# PIC32MZ1024EFM064 device description
Architecture: MIPS; Family: PIC32MZEF; Series: PIC32MZ
Registers are 32-bit, read-write, no defined reset value unless marked. A register's access mark holds for its fields unless they carry their own. Offsets are from the block's base; [hi:lo] are bit positions; {n}, {i} and the like mark numbered series; 'fields as' and 'values as' point back to an identical list.

## CFG
Instances: CFG 0x1f800000 in periph_pb1_std
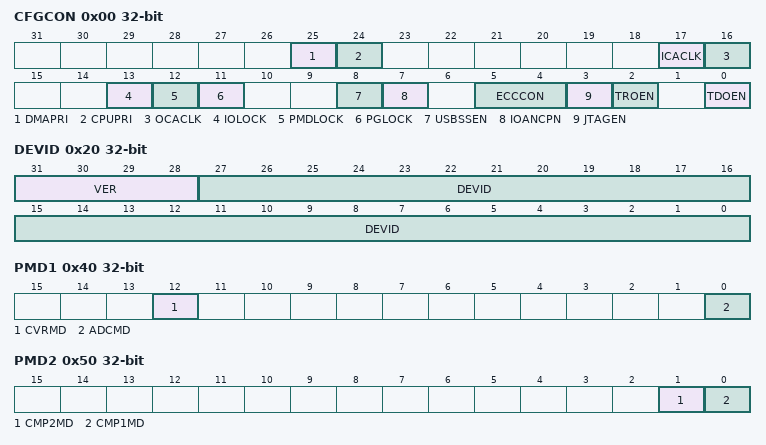
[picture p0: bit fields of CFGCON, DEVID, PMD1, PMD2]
0x00 CFGCON — Configuration Control Register
  [25] DMAPRI — DMA Read and DMA Write Arbitration Priority to SRAM bit(1)
    1=DMA gets High Priority access to SRAM; 0=DMA uses Least Recently Serviced Arbitration (same as other initiators)
  [24] CPUPRI — CPU Arbitration Priority to SRAM When Servicing an Interrupt bit(1)
    1=CPU gets High Priority access to SRAM; 0=CPU uses Least Recently Serviced Arbitration (same as other initiators)
  [17] ICACLK — Input Capture Alternate Clock Selection bit(1)
    1=Input Capture modules use an alternative Timer pair as their timebase clock; 0=All Input Capture modules use Timer2/3 as their timebase clock
  [16] OCACLK — Output Compare Alternate Clock Selection bit(1)
    1=Output Compare modules use an alternative Timer pair as their timebase clock; 0=All Output Compare modules use Timer2/3 as their timebase clock
  [13] IOLOCK — Peripheral Pin Select Lock bit(1)
    1=Peripheral Pin Select is locked. Writes to PPS registers are not allowed; 0=Peripheral Pin Select is not locked. Writes to PPS registers are allowed
  [12] PMDLOCK — Peripheral Module Disable bit(1)
    1=Peripheral module is locked. Writes to PMD registers are not allowed; 0=Peripheral module is not locked. Writes to PMD registers are allowed
  [11] PGLOCK — Permission Group Lock bit(1)
    1=Permission Group registers are locked. Writes to PG registers are not allowed; 0=Permission Group registers are not locked. Writes to PG registers are allowed
  [8] USBSSEN — USB Suspend Sleep Enable bit(1)
    1=USB PHY clock is shut down when Sleep mode is active; 0=USB PHY clock continues to run when Sleep is active
  [7] IOANCPN
  [5:4] ECCCON — Flash ECC Configuration bits
    3=ECC and dynamic ECC are disabled (ECCCON bits are writable); 2=ECC and dynamic ECC are disabled (ECCCON bits are locked); 1=Dynamic Flash ECC is enabled (ECCCON bits are locked); 0=Flash ECC is enabled (ECCCON bits are locked; disables word Flash writes)
  [3] JTAGEN — JTAG Port Enable bit
    1=Enable the JTAG port; 0=Disable the JTAG port
  [2] TROEN — Trace Output Enable bit
    1=Enable trace outputs and start trace clock (trace probe must be present); 0=Disable trace outputs and stop trace clock
  [0] TDOEN — TDO Enable for 2-Wire JTAG
    1=2-wire JTAG protocol uses TDO; 0=2-wire JTAG protocol does not use TDO
0x20 DEVID — Device and Revision ID Register
  [31:28] VER, [27:0] DEVID
0x30 SYSKEY
0x40 PMD1
  [12] CVRMD, [0] ADCMD
0x50 PMD2
  [1] CMP2MD, [0] CMP1MD
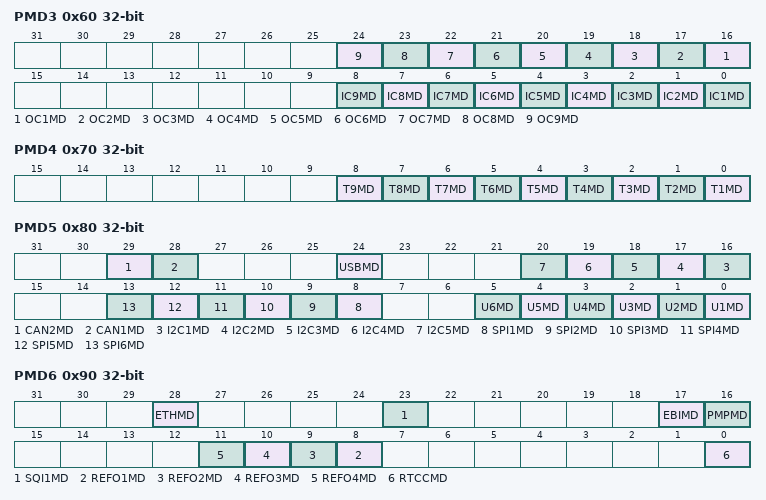
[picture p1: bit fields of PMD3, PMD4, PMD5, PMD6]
0x60 PMD3
  [n+15] OC{n}MD (n=1..9), [n-1] IC{n}MD (n=1..9)
0x70 PMD4
  [n-1] T{n}MD (n=1..9)
0x80 PMD5
  [29] CAN2MD, [28] CAN1MD, [24] USBMD, [n+15] I2C{n}MD (n=1..5), [n+7] SPI{n}MD (n=1..6), [n-1] U{n}MD (n=1..6)
0x90 PMD6
  [28] ETHMD, [23] SQI1MD, [17] EBIMD, [16] PMPMD, [n+7] REFO{n}MD (n=1..4), [0] RTCCMD
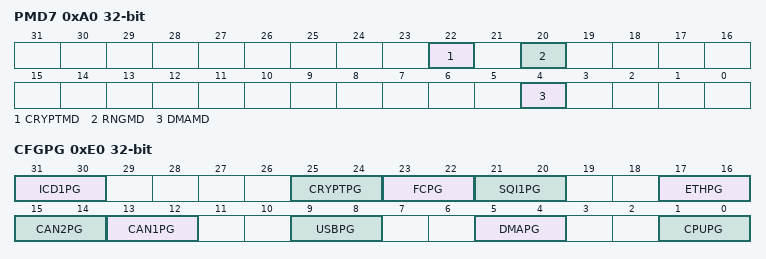
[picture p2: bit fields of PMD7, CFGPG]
0xA0 PMD7
  [22] CRYPTMD, [20] RNGMD, [4] DMAMD
0xE0 CFGPG — Permission Group Configuration Register
  [31:30] ICD1PG
  [25:24] CRYPTPG — Crypto Engine Permission Group bits
    {v}=Initiator is assigned to Permission Group {v} (v=0..3)
  [23:22] FCPG
  [21:20] SQI1PG
  [17:16] ETHPG
  [15:14] CAN2PG
  [13:12] CAN1PG
  [9:8] USBPG
  [5:4] DMAPG
  [1:0] CPUPG
Value list DEVID__VER: 0x10000000=Revision A1; 0x30000000=Revision A3; 0x60000000=Revision B2
Value list CFGCON__IOANCPEN: 128=Charge pump is enabled; 0=Charge pump is disabled

## CMP
Instances: CMP 0x1f84c000 in periph_pb3_std
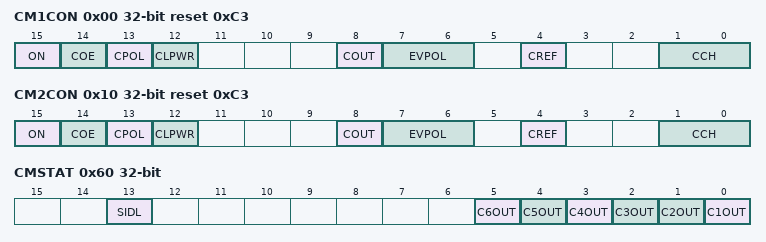
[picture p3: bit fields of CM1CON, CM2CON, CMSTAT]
0x00 CM1CON reset 0xC3 — Comparator Control Register
  [15] ON — Comparator ON bit
    1=Module is enabled. Setting this bit does not affect the other bits in this register; 0=Module is disabled and does not consume current. Clearing this bit does not affect the other bits in this register
  [14] COE — Comparator Output Enable bit
    1=Comparator output is driven on the output CxOUT pin; 0=Comparator output is not driven on the output CxOUT pin
  [13] CPOL — Comparator Output Inversion bit
    1=Output is inverted; 0=Output is not inverted
  [12] CLPWR
  [8] COUT — Comparator Output bit
    1=Output of the Comparator is a 1; 0=Output of the Comparator is a 0
  [7:6] EVPOL — Interrupt Event Polarity Select bits
    3=Comparator interrupt is generated on a low-to-high or high-to-low transition of the comparator output; 2=Comparator interrupt is generated on a high-to-low transition of the comparator output; 1=Comparator interrupt is generated on a low-to-high transition of the comparator output; 0=Comparator interrupt generation is disabled
  [4] CREF — Comparator Positive Input Configure bit
    1=Comparator non-inverting input is connected to the internal CVref; 0=Comparator non-inverting input is connected to the CxINA pin
  [1:0] CCH — Comparator Negative Input Select bits for Comparator
    3=Comparator inverting input is connected to the IVREF; 2=Comparator inverting input is connected to the CxIND pin; 1=Comparator inverting input is connected to the CxINC pin; 0=Comparator inverting input is connected to the CxINB pin
0x10 CM2CON reset 0xC3 — Comparator Control Register
  fields as CM1CON
0x60 CMSTAT — Comparator Status Register
  [13] SIDL — Stop in Idle Control bit
    1=All Comparator modules are disabled in Idle mode; 0=All Comparator modules continue to operate in the Idle mode
  [n-1] C{n}OUT (n=3..6)
  [1] C2OUT — Comparator Output bit
    1=Output of Comparator 2 is a 1; 0=Output of Comparator 2 is a 0
  [0] C1OUT — Comparator Output bit
    1=Output of Comparator 1 is a 1; 0=Output of Comparator 1 is a 0

## Notices in the file
Copyright (c) 2017 Microchip Technology Inc.
SPDX-License-Identifier: Apache-2.0
Licensed under the Apache License, Version 2.0 (the "License");
you may not use this file except in compliance with the License.
You may obtain a copy of the License at
http://www.apache.org/licenses/LICENSE-2.0
Unless required by applicable law or agreed to in writing, software
distributed under the License is distributed on an "AS IS" BASIS,
WITHOUT WARRANTIES OR CONDITIONS OF ANY KIND, either express or implied.
See the License for the specific language governing permissions and
limitations under the License.
